# LargeDummyDevice register map
File version: 1.0
Registers are 32-bit, read-write, no defined reset value unless marked. A register's access mark holds for its fields unless they carry their own. Offsets are from the block's base; [hi:lo] are bit positions.

## PERIPHERAL_89
Base 0x40058000
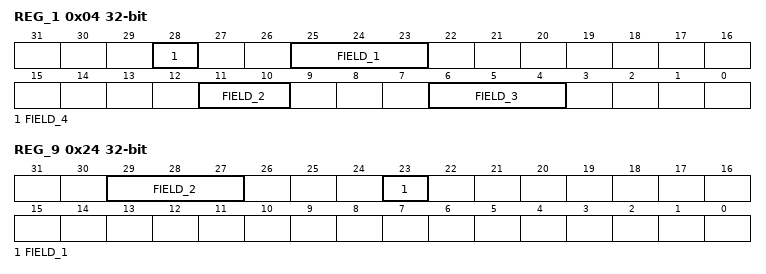
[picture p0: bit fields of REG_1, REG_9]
0x04 REG_1 — Register 1
  [28] FIELD_4, [25:23] FIELD_1, [11:10] FIELD_2, [6:4] FIELD_3
0x08 REG_2 — Register 2
  [35:31] FIELD_15, [33:29] FIELD_13, [27] FIELD_3, [27:25] FIELD_4, [19:18] FIELD_2, [20:16] FIELD_10, [17:15] FIELD_12, [15:14] FIELD_9, [11:8] FIELD_5, [11:8] FIELD_14, [5] FIELD_7, [7:4] FIELD_6, [7:4] FIELD_11, [4:2] FIELD_1, [6:2] FIELD_16, [4:2] FIELD_17, [5:1] FIELD_8
0x0C REG_3 — Register 3
  [33:31] FIELD_19, [34:31] FIELD_23, [32:29] FIELD_18, [31:28] FIELD_13, [30:26] FIELD_8, [26] FIELD_25, [25] FIELD_16, [27:24] FIELD_4, [25:22] FIELD_6, [21] FIELD_22, [24:20] FIELD_3, [22:20] FIELD_21, [21:19] FIELD_5, [19:18] FIELD_7, [22:18] FIELD_12, [17] FIELD_28, [14] FIELD_10, [14:11] FIELD_9, [12:11] FIELD_15, [10] FIELD_20, [11:8] FIELD_2, [11:7] FIELD_1, [6:4] FIELD_14, [7:4] FIELD_17, [5:4] FIELD_26, [6:4] FIELD_27, [5:3] FIELD_11, [5:3] FIELD_24
0x10 REG_4 — Register 4
  [33:29] FIELD_2, [28] FIELD_1, [26:24] FIELD_8, [22:18] FIELD_3, [14] FIELD_7, [14:12] FIELD_4, [12:8] FIELD_9, [7:5] FIELD_5, [2:0] FIELD_6
0x14 REG_5 — Register 5
  [30] FIELD_11, [27:25] FIELD_17, [24:23] FIELD_10, [25:22] FIELD_5, [22:20] FIELD_6, [23:19] FIELD_15, [21:18] FIELD_7, [20:17] FIELD_2, [19:16] FIELD_8, [18:15] FIELD_16, [13:10] FIELD_12, [12:10] FIELD_13, [7] FIELD_4, [8:6] FIELD_9, [8:6] FIELD_18, [7:5] FIELD_19, [5:3] FIELD_1, [6:3] FIELD_14, [2:0] FIELD_3
0x18 REG_6 — Register 6
  [33:31] FIELD_7, [31:30] FIELD_6, [31:28] FIELD_8, [28:24] FIELD_10, [26:22] FIELD_9, [24:20] FIELD_1, [14] FIELD_4, [9:6] FIELD_2, [7:3] FIELD_5, [3:1] FIELD_3
0x1C REG_7 — Register 7
  [33:30] FIELD_4, [26] FIELD_3, [17:16] FIELD_6, [18:15] FIELD_2, [14:12] FIELD_5, [2] FIELD_1
0x20 REG_8 — Register 8
  [23] FIELD_5, [23:19] FIELD_6, [16:14] FIELD_2, [14:10] FIELD_4, [8:6] FIELD_1, [5:2] FIELD_3
0x24 REG_9 — Register 9
  [29:27] FIELD_2, [23] FIELD_1
0x28 REG_10 — Register 10
  [31:29] FIELD_24, [31:28] FIELD_11, [28:27] FIELD_9, [27] FIELD_19, [27] FIELD_28, [30:26] FIELD_1, [29:25] FIELD_6, [25:23] FIELD_5, [24:23] FIELD_21, [24:22] FIELD_31, [21] FIELD_10, [22:20] FIELD_8, [22:19] FIELD_30, [19:18] FIELD_23, [21:17] FIELD_7, [14:13] FIELD_18, [14:13] FIELD_27, [15:11] FIELD_4, [11] FIELD_16, [13:9] FIELD_20, [7] FIELD_2, [10:6] FIELD_12, [10:6] FIELD_13, [9:5] FIELD_17, [7:4] FIELD_26, [6:3] FIELD_22, [6:2] FIELD_29, [1] FIELD_3, [5:1] FIELD_25, [1:0] FIELD_14, [2:0] FIELD_15
0x2C REG_11 — Register 11
  [31] FIELD_3, [35:31] FIELD_27, [31:30] FIELD_14, [29] FIELD_17, [30:28] FIELD_18, [27:24] FIELD_9, [27:23] FIELD_2, [22] FIELD_1, [22:21] FIELD_13, [23:21] FIELD_20, [21:20] FIELD_26, [20:19] FIELD_16, [20:17] FIELD_11, [15:14] FIELD_4, [18:14] FIELD_10, [18:14] FIELD_21, [13:11] FIELD_24, [12:11] FIELD_25, [13:9] FIELD_12, [12:8] FIELD_8, [11:7] FIELD_6, [10:7] FIELD_28, [7:5] FIELD_7, [7:5] FIELD_15, [5:4] FIELD_5, [5:2] FIELD_19, [4:2] FIELD_22, [1:0] FIELD_23
0x30 REG_12 — Register 12
  [30:27] FIELD_6, [26:23] FIELD_14, [23:21] FIELD_9, [23:20] FIELD_15, [20:18] FIELD_8, [19:18] FIELD_10, [18:16] FIELD_11, [15] FIELD_2, [15] FIELD_7, [16:14] FIELD_5, [16:13] FIELD_13, [10] FIELD_12, [11:9] FIELD_1, [13:9] FIELD_4, [7:3] FIELD_3
0x34 REG_13 — Register 13
  [31:29] FIELD_6, [29:28] FIELD_7, [31:27] FIELD_11, [25:24] FIELD_4, [24:21] FIELD_2, [18] FIELD_3, [15:14] FIELD_8, [17:13] FIELD_9, [10:9] FIELD_5, [9:5] FIELD_12, [6:4] FIELD_10, [7:3] FIELD_1, [5:3] FIELD_13
0x38 REG_14 — Register 14
  [32:29] FIELD_19, [28] FIELD_18, [28:26] FIELD_4, [26] FIELD_6, [29:26] FIELD_25, [28:24] FIELD_12, [25:23] FIELD_11, [26:23] FIELD_24, [21] FIELD_1, [21:20] FIELD_27, [19:18] FIELD_13, [16:15] FIELD_3, [16:15] FIELD_20, [15] FIELD_23, [14] FIELD_8, [14:11] FIELD_22, [12:11] FIELD_28, [13:10] FIELD_14, [11:9] FIELD_7, [9:7] FIELD_10, [9:5] FIELD_5, [6:5] FIELD_15, [7:4] FIELD_26, [4:2] FIELD_16, [6:2] FIELD_17, [4:1] FIELD_9, [3:0] FIELD_2, [0] FIELD_21
0x3C REG_15 — Register 15
  [34:31] FIELD_1, [10:8] FIELD_2
